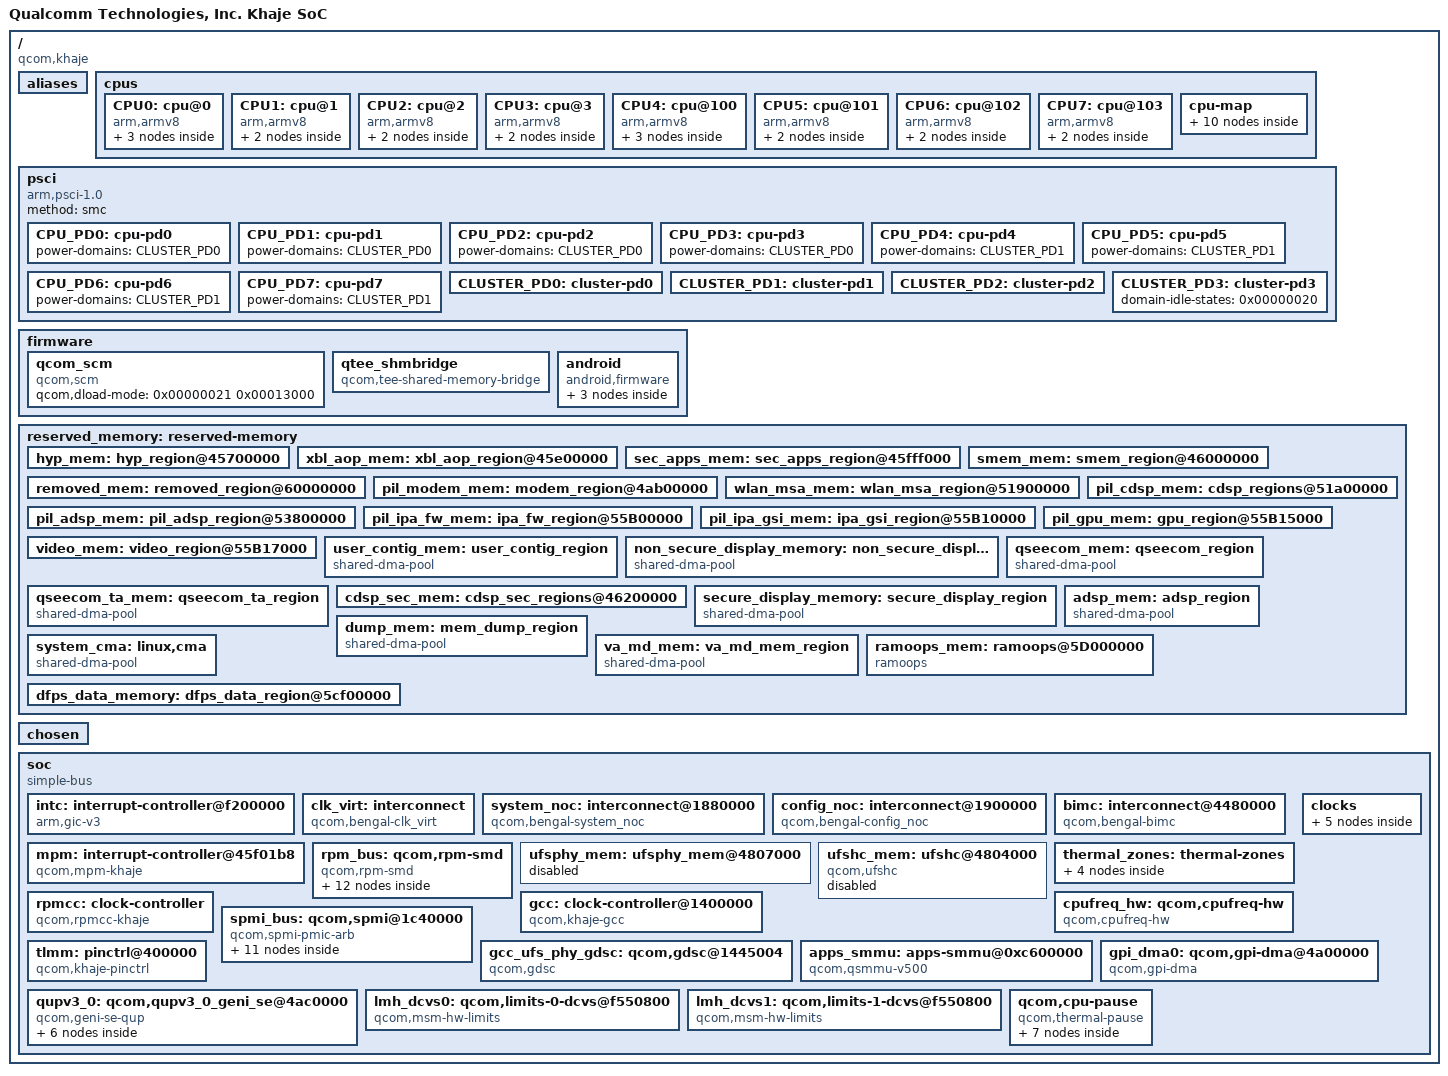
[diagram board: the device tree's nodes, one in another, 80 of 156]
/*
 * DT da SoC Khaje (subconjunto curado) gerada por tools/curate_dt.py.
 * Fonte: khaje-base-reference.dts, sha256 a0517193be3da264...
 * Nao revisado por upstream nem validado em hardware. Nao flashar.
 * Licenca: a definir antes de submissao (base Qualcomm, revisar).
 */

/ {
	model = "Qualcomm Technologies, Inc. Khaje SoC";
	compatible = "qcom,khaje";
	qcom,msm-id = <0x00000206 0x00010000>;
	interrupt-parent = <&intc>;
	#address-cells = <0x00000002>;
	#size-cells = <0x00000002>;
	qcom,board-id = <0x00000000 0x00000000>;
	aliases {
		ufshc1 = "/soc/ufshc@4804000";
		serial0 = "/soc/qcom,qupv3_0_geni_se@4ac0000/qcom,qup_uart@4a90000";
		hsuart0 = "/soc/qcom,qupv3_0_geni_se@4ac0000/qcom,qup_uart@4a8c000";
		spi0 = "/soc/qcom,qupv3_0_geni_se@4ac0000/spi@4a80000";
		i2c0 = "/soc/qcom,qupv3_0_geni_se@4ac0000/i2c@4a84000";
		i2c1 = "/soc/qcom,qupv3_0_geni_se@4ac0000/i2c@4a88000";
		i2c2 = "/soc/qcom,qupv3_0_geni_se@4ac0000/i2c@4a90000";
	};
	cpus {
		#address-cells = <0x00000002>;
		#size-cells = <0x00000000>;
		CPU0: cpu@0 {
			device_type = "cpu";
			compatible = "arm,armv8";
			reg = <0x00000000 0x00000000>;
			capacity-dmips-mhz = <0x00000400>;
			dynamic-power-coefficient = <0x00000064>;
			cpu-idle-states = <0x00000002>;
			power-domains = <&CPU_PD0>;
			power-domain-names = "psci";
			enable-method = "psci";
			next-level-cache = <&L2_0>;
			qcom,freq-domain = <&cpufreq_hw 0x00000000 0x00000007>;
			qcom,lmh-dcvs = <&lmh_dcvs0>;
			#cooling-cells = <0x00000002>;
			phandle = <0x00000011>;
			L2_0: l2-cache {
				compatible = "arm,arch-cache";
				cache-level = <0x00000002>;
				phandle = <0x00000004>;
			};
			L1_I_0: l1-icache {
				compatible = "arm,arch-cache";
				phandle = <0x00000127>;
			};
			L1_D_0: l1-dcache {
				compatible = "arm,arch-cache";
				phandle = <0x00000128>;
			};
		};
		CPU1: cpu@1 {
			device_type = "cpu";
			compatible = "arm,armv8";
			reg = <0x00000000 0x00000001>;
			capacity-dmips-mhz = <0x00000400>;
			dynamic-power-coefficient = <0x00000064>;
			cpu-idle-states = <0x00000002>;
			power-domains = <&CPU_PD1>;
			power-domain-names = "psci";
			enable-method = "psci";
			next-level-cache = <&L2_0>;
			qcom,freq-domain = <&cpufreq_hw 0x00000000 0x00000007>;
			qcom,lmh-dcvs = <&lmh_dcvs0>;
			phandle = <0x00000012>;
			L1_I_1: l1-icache {
				compatible = "arm,arch-cache";
				phandle = <0x00000129>;
			};
			L1_D_1: l1-dcache {
				compatible = "arm,arch-cache";
				phandle = <0x0000012a>;
			};
		};
		CPU2: cpu@2 {
			device_type = "cpu";
			compatible = "arm,armv8";
			reg = <0x00000000 0x00000002>;
			capacity-dmips-mhz = <0x00000400>;
			dynamic-power-coefficient = <0x00000064>;
			cpu-idle-states = <0x00000002>;
			power-domains = <&CPU_PD2>;
			power-domain-names = "psci";
			enable-method = "psci";
			next-level-cache = <&L2_0>;
			qcom,freq-domain = <&cpufreq_hw 0x00000000 0x00000007>;
			qcom,lmh-dcvs = <&lmh_dcvs0>;
			phandle = <0x00000013>;
			L1_I_2: l1-icache {
				compatible = "arm,arch-cache";
				phandle = <0x0000012b>;
			};
			L1_D_2: l1-dcache {
				compatible = "arm,arch-cache";
				phandle = <0x0000012c>;
			};
		};
		CPU3: cpu@3 {
			device_type = "cpu";
			compatible = "arm,armv8";
			reg = <0x00000000 0x00000003>;
			capacity-dmips-mhz = <0x00000400>;
			dynamic-power-coefficient = <0x00000064>;
			cpu-idle-states = <0x00000002>;
			power-domains = <&CPU_PD3>;
			power-domain-names = "psci";
			enable-method = "psci";
			next-level-cache = <&L2_0>;
			qcom,freq-domain = <&cpufreq_hw 0x00000000 0x00000007>;
			qcom,lmh-dcvs = <&lmh_dcvs0>;
			phandle = <0x00000014>;
			L1_I_3: l1-icache {
				compatible = "arm,arch-cache";
				phandle = <0x0000012d>;
			};
			L1_D_3: l1-dcache {
				compatible = "arm,arch-cache";
				phandle = <0x0000012e>;
			};
		};
		CPU4: cpu@100 {
			device_type = "cpu";
			compatible = "arm,armv8";
			reg = <0x00000000 0x00000100>;
			cpu-idle-states = <0x0000000a>;
			power-domains = <&CPU_PD4>;
			power-domain-names = "psci";
			enable-method = "psci";
			capacity-dmips-mhz = <0x00000666>;
			dynamic-power-coefficient = <0x0000011a>;
			next-level-cache = <&L2_1>;
			qcom,freq-domain = <&cpufreq_hw 0x00000001 0x00000007>;
			qcom,lmh-dcvs = <&lmh_dcvs1>;
			#cooling-cells = <0x00000002>;
			phandle = <0x00000015>;
			L2_1: l2-cache {
				compatible = "arm,arch-cache";
				cache-level = <0x00000002>;
				phandle = <0x0000000c>;
			};
			L1_I_100: l1-icache {
				compatible = "arm,arch-cache";
				phandle = <0x0000012f>;
			};
			L1_D_100: l1-dcache {
				compatible = "arm,arch-cache";
				phandle = <0x00000130>;
			};
		};
		CPU5: cpu@101 {
			device_type = "cpu";
			compatible = "arm,armv8";
			reg = <0x00000000 0x00000101>;
			capacity-dmips-mhz = <0x00000666>;
			dynamic-power-coefficient = <0x0000011a>;
			cpu-idle-states = <0x0000000a>;
			power-domains = <&CPU_PD5>;
			power-domain-names = "psci";
			enable-method = "psci";
			next-level-cache = <&L2_1>;
			qcom,freq-domain = <&cpufreq_hw 0x00000001 0x00000007>;
			qcom,lmh-dcvs = <&lmh_dcvs1>;
			phandle = <0x00000016>;
			L1_I_101: l1-icache {
				compatible = "arm,arch-cache";
				phandle = <0x00000131>;
			};
			L1_D_101: l1-dcache {
				compatible = "arm,arch-cache";
				phandle = <0x00000132>;
			};
		};
		CPU6: cpu@102 {
			device_type = "cpu";
			compatible = "arm,armv8";
			reg = <0x00000000 0x00000102>;
			capacity-dmips-mhz = <0x00000666>;
			dynamic-power-coefficient = <0x0000011a>;
			enable-method = "psci";
			cpu-idle-states = <0x0000000a>;
			power-domains = <&CPU_PD6>;
			power-domain-names = "psci";
			next-level-cache = <&L2_1>;
			qcom,freq-domain = <&cpufreq_hw 0x00000001 0x00000007>;
			qcom,lmh-dcvs = <&lmh_dcvs1>;
			phandle = <0x00000017>;
			L1_I_102: l1-icache {
				compatible = "arm,arch-cache";
				phandle = <0x00000133>;
			};
			L1_D_102: l1-dcache {
				compatible = "arm,arch-cache";
				phandle = <0x00000134>;
			};
		};
		CPU7: cpu@103 {
			device_type = "cpu";
			compatible = "arm,armv8";
			reg = <0x00000000 0x00000103>;
			capacity-dmips-mhz = <0x00000666>;
			dynamic-power-coefficient = <0x0000011a>;
			enable-method = "psci";
			cpu-idle-states = <0x0000000a>;
			power-domains = <&CPU_PD7>;
			power-domain-names = "psci";
			next-level-cache = <&L2_1>;
			qcom,freq-domain = <&cpufreq_hw 0x00000001 0x00000007>;
			qcom,lmh-dcvs = <&lmh_dcvs1>;
			phandle = <0x00000018>;
			L1_I_103: l1-icache {
				compatible = "arm,arch-cache";
				phandle = <0x00000135>;
			};
			L1_D_103: l1-dcache {
				compatible = "arm,arch-cache";
				phandle = <0x00000136>;
			};
		};
		cpu-map {
			cluster0 {
				core0 {
					cpu = <0x00000011>;
				};
				core1 {
					cpu = <0x00000012>;
				};
				core2 {
					cpu = <0x00000013>;
				};
				core3 {
					cpu = <0x00000014>;
				};
			};
			cluster1 {
				core0 {
					cpu = <0x00000015>;
				};
				core1 {
					cpu = <0x00000016>;
				};
				core2 {
					cpu = <0x00000017>;
				};
				core3 {
					cpu = <0x00000018>;
				};
			};
		};
	};
	psci {
		compatible = "arm,psci-1.0";
		method = "smc";
		CPU_PD0: cpu-pd0 {
			#power-domain-cells = <0x00000000>;
			power-domains = <&CLUSTER_PD0>;
			phandle = <0x00000003>;
		};
		CPU_PD1: cpu-pd1 {
			#power-domain-cells = <0x00000000>;
			power-domains = <&CLUSTER_PD0>;
			phandle = <0x00000007>;
		};
		CPU_PD2: cpu-pd2 {
			#power-domain-cells = <0x00000000>;
			power-domains = <&CLUSTER_PD0>;
			phandle = <0x00000008>;
		};
		CPU_PD3: cpu-pd3 {
			#power-domain-cells = <0x00000000>;
			power-domains = <&CLUSTER_PD0>;
			phandle = <0x00000009>;
		};
		CPU_PD4: cpu-pd4 {
			#power-domain-cells = <0x00000000>;
			power-domains = <&CLUSTER_PD1>;
			phandle = <0x0000000b>;
		};
		CPU_PD5: cpu-pd5 {
			#power-domain-cells = <0x00000000>;
			power-domains = <&CLUSTER_PD1>;
			phandle = <0x0000000e>;
		};
		CPU_PD6: cpu-pd6 {
			#power-domain-cells = <0x00000000>;
			power-domains = <&CLUSTER_PD1>;
			phandle = <0x0000000f>;
		};
		CPU_PD7: cpu-pd7 {
			#power-domain-cells = <0x00000000>;
			power-domains = <&CLUSTER_PD1>;
			phandle = <0x00000010>;
		};
		CLUSTER_PD0: cluster-pd0 {
			#power-domain-cells = <0x00000000>;
			power-domains = <&CLUSTER_PD2>;
			domain-idle-states = <0x0000001c>;
			phandle = <0x00000019>;
		};
		CLUSTER_PD1: cluster-pd1 {
			#power-domain-cells = <0x00000000>;
			power-domains = <&CLUSTER_PD2>;
			domain-idle-states = <0x0000001d>;
			phandle = <0x0000001a>;
		};
		CLUSTER_PD2: cluster-pd2 {
			#power-domain-cells = <0x00000000>;
			power-domains = <&CLUSTER_PD3>;
			domain-idle-states = <0x0000001f>;
			phandle = <0x0000001b>;
		};
		CLUSTER_PD3: cluster-pd3 {
			#power-domain-cells = <0x00000000>;
			domain-idle-states = <0x00000020>;
			phandle = <0x0000001e>;
		};
	};
	firmware: firmware {
		phandle = <0x00000137>;
		qcom_scm {
			compatible = "qcom,scm";
			qcom,dload-mode = <0x00000021 0x00013000>;
		};
		qtee_shmbridge {
			compatible = "qcom,tee-shared-memory-bridge";
		};
		android {
			compatible = "android,firmware";
			vbmeta {
				compatible = "android,vbmeta";
				parts = "vbmeta,boot,system,vendor,dtbo,recovery";
			};
			fstab {
				compatible = "android,fstab";
				vendor {
					compatible = "android,vendor";
					dev = "/dev/block/platform/soc/4744000.sdhci/by-name/vendor";
					type = "ext4";
					mnt_flags = "ro,barrier=1,discard";
					fsmgr_flags = "wait,slotselect,avb";
					status = "okay";
				};
			};
		};
	};
	reserved_memory: reserved-memory {
		#address-cells = <0x00000002>;
		#size-cells = <0x00000002>;
		ranges;
		phandle = <0x00000138>;
		hyp_mem: hyp_region@45700000 {
			no-map;
			reg = <0x00000000 0x45700000 0x00000000 0x00600000>;
			phandle = <0x00000139>;
		};
		xbl_aop_mem: xbl_aop_region@45e00000 {
			no-map;
			reg = <0x00000000 0x45e00000 0x00000000 0x00140000>;
			phandle = <0x0000013a>;
		};
		sec_apps_mem: sec_apps_region@45fff000 {
			no-map;
			reg = <0x00000000 0x45fff000 0x00000000 0x00001000>;
			phandle = <0x0000013b>;
		};
		smem_mem: smem_region@46000000 {
			no-map;
			reg = <0x00000000 0x46000000 0x00000000 0x00200000>;
			phandle = <0x000000ca>;
		};
		removed_mem: removed_region@60000000 {
			no-map;
			reg = <0x00000000 0x60000000 0x00000000 0x03900000>;
			phandle = <0x0000013c>;
		};
		pil_modem_mem: modem_region@4ab00000 {
			no-map;
			reg = <0x00000000 0x4ab00000 0x00000000 0x06900000>;
			phandle = <0x000000da>;
		};
		wlan_msa_mem: wlan_msa_region@51900000 {
			no-map;
			reg = <0x00000000 0x51900000 0x00000000 0x00100000>;
			phandle = <0x0000013d>;
		};
		pil_cdsp_mem: cdsp_regions@51a00000 {
			no-map;
			reg = <0x00000000 0x51a00000 0x00000000 0x01a00000>;
			phandle = <0x00000096>;
		};
		pil_adsp_mem: pil_adsp_region@53800000 {
			no-map;
			reg = <0x00000000 0x53800000 0x00000000 0x02300000>;
			phandle = <0x00000091>;
		};
		pil_ipa_fw_mem: ipa_fw_region@55B00000 {
			no-map;
			reg = <0x00000000 0x55b00000 0x00000000 0x00010000>;
			phandle = <0x000000e0>;
		};
		pil_ipa_gsi_mem: ipa_gsi_region@55B10000 {
			no-map;
			reg = <0x00000000 0x55b10000 0x00000000 0x00005000>;
			phandle = <0x0000013e>;
		};
		pil_gpu_mem: gpu_region@55B15000 {
			no-map;
			reg = <0x00000000 0x55b15000 0x00000000 0x00002000>;
			phandle = <0x0000013f>;
		};
		video_mem: video_region@55B17000 {
			no-map;
			reg = <0x00000000 0x55b17000 0x00000000 0x00700000>;
			phandle = <0x00000140>;
		};
		user_contig_mem: user_contig_region {
			compatible = "shared-dma-pool";
			alloc-ranges = <0x00000000 0x00000000 0x00000000 0xffffffff>;
			reusable;
			alignment = <0x00000000 0x00400000>;
			size = <0x00000000 0x01000000>;
			phandle = <0x00000089>;
		};
		non_secure_display_memory: non_secure_display_region {
			compatible = "shared-dma-pool";
			reusable;
			alloc-ranges = <0x00000000 0x00000000 0x00000000 0xffffffff>;
			size = <0x00000000 0x0a400000>;
			alignment = <0x00000000 0x00400000>;
			phandle = <0x000000f8>;
		};
		qseecom_mem: qseecom_region {
			compatible = "shared-dma-pool";
			alloc-ranges = <0x00000000 0x00000000 0x00000000 0xffffffff>;
			reusable;
			alignment = <0x00000000 0x00400000>;
			size = <0x00000000 0x01400000>;
			phandle = <0x00000087>;
		};
		qseecom_ta_mem: qseecom_ta_region {
			compatible = "shared-dma-pool";
			alloc-ranges = <0x00000000 0x00000000 0x00000000 0xffffffff>;
			reusable;
			alignment = <0x00000000 0x00400000>;
			size = <0x00000000 0x01000000>;
			phandle = <0x00000088>;
		};
		cdsp_sec_mem: cdsp_sec_regions@46200000 {
			no-map;
			reg = <0x00000000 0x46200000 0x00000000 0x01e00000>;
			phandle = <0x000000f6>;
		};
		secure_display_memory: secure_display_region {
			compatible = "shared-dma-pool";
			alloc-ranges = <0x00000000 0x00000000 0x00000000 0xffffffff>;
			reusable;
			alignment = <0x00000000 0x00400000>;
			size = <0x00000000 0x05c00000>;
			phandle = <0x000000f7>;
		};
		adsp_mem: adsp_region {
			compatible = "shared-dma-pool";
			alloc-ranges = <0x00000000 0x00000000 0x00000000 0xffffffff>;
			reusable;
			alignment = <0x00000000 0x00400000>;
			size = <0x00000000 0x00800000>;
			phandle = <0x000000d1>;
		};
		dump_mem: mem_dump_region {
			compatible = "shared-dma-pool";
			alloc-ranges = <0x00000000 0x00000000 0x00000000 0xffffffff>;
			reusable;
			size = <0x00000000 0x00800000>;
			phandle = <0x00000099>;
		};
		system_cma: linux,cma {
			compatible = "shared-dma-pool";
			alloc-ranges = <0x00000000 0x00000000 0x00000000 0xffffffff>;
			reusable;
			alignment = <0x00000000 0x00400000>;
			size = <0x00000000 0x02000000>;
			linux,cma-default;
			phandle = <0x000000ff>;
		};
		va_md_mem: va_md_mem_region {
			compatible = "shared-dma-pool";
			alloc-ranges = <0x00000000 0x00000000 0x00000000 0xffffffff>;
			reusable;
			size = <0x00000000 0x01000000>;
			phandle = <0x000000c8>;
		};
		ramoops_mem: ramoops@5D000000 {
			compatible = "ramoops";
			reg = <0x00000000 0x5d000000 0x00000000 0x00200000>;
			record-size = <0x00040000>;
			pmsg-size = <0x00100000>;
			console-size = <0x00080000>;
			phandle = <0x00000141>;
		};
		dfps_data_memory: dfps_data_region@5cf00000 {
			phandle = <0x000002ef>;
			label = "dfps_data_region";
			reg = <0x00000000 0x5cf00000 0x00000000 0x00100000>;
		};
	};
	chosen {
	};
	soc: soc {
		#address-cells = <0x00000001>;
		#size-cells = <0x00000001>;
		ranges = <0x00000000 0x00000000 0x00000000 0xffffffff>;
		compatible = "simple-bus";
		phandle = <0x00000142>;
		intc: interrupt-controller@f200000 {
			compatible = "arm,gic-v3";
			#interrupt-cells = <0x00000003>;
			interrupt-controller;
			interrupt-parent = <&intc>;
			#redistributor-regions = <0x00000001>;
			redistributor-stride = <0x00000000 0x00020000>;
			reg = <0x0f200000 0x00010000 0x0f300000 0x00100000>;
			interrupts = <0x00000001 0x00000009 0x00000004>;
			phandle = <0x00000001>;
		};
		clk_virt: interconnect {
			compatible = "qcom,bengal-clk_virt";
			qcom,keepalive;
			#interconnect-cells = <0x00000001>;
			clock-names = "bus", "bus_a";
			clocks = <&rpmcc 0x0000006a &rpmcc 0x0000006b>;
			phandle = <0x00000101>;
		};
		system_noc: interconnect@1880000 {
			compatible = "qcom,bengal-system_noc";
			reg = <0x01880000 0x0005f080>;
			#interconnect-cells = <0x00000001>;
			qcom,keepalive;
			clock-names = "bus", "bus_a";
			clocks = <&rpmcc 0x00000004 &rpmcc 0x00000005 &gcc 0x00000038 &gcc 0x00000074>;
			phandle = <0x0000008a>;
		};
		config_noc: interconnect@1900000 {
			compatible = "qcom,bengal-config_noc";
			reg = <0x01900000 0x00006200>;
			#interconnect-cells = <0x00000001>;
			qcom,keepalive;
			clock-names = "bus", "bus_a";
			clocks = <&rpmcc 0x0000001c &rpmcc 0x0000001d>;
			phandle = <0x0000008c>;
		};
		bimc: interconnect@4480000 {
			compatible = "qcom,bengal-bimc";
			reg = <0x04480000 0x00080000>;
			#interconnect-cells = <0x00000001>;
			qcom,util-factor = <0x00000099>;
			qcom,keepalive;
			clock-names = "bus", "bus_a";
			clocks = <&rpmcc 0x00000006 &rpmcc 0x00000007>;
			phandle = <0x0000008b>;
		};
		mpm: interrupt-controller@45f01b8 {
			compatible = "qcom,mpm-khaje", "qcom,mpm";
			reg = <0x045f01b8 0x00001000 0x0f111008 0x00000004 0x0f121000 0x00001000>;
			reg-names = "vmpm", "ipc", "timer";
			interrupts = <0x00000000 0x000000c5 0x00000001>;
			qcom,num-mpm-irqs = <0x00000060>;
			interrupt-controller;
			interrupt-parent = <&intc>;
			#interrupt-cells = <0x00000002>;
			phandle = <0x000000d5>;
		};
		rpm_bus: qcom,rpm-smd {
			compatible = "qcom,rpm-smd";
			rpm-channel-name = "rpm_requests";
			interrupts = <0x00000000 0x000000c2 0x00000001>;
			power-domains = <&CLUSTER_PD3>;
			rpm-channel-type = <0x0000000f>;
			phandle = <0x000001a5>;
			rpm-regulator-smpa3 {
				compatible = "qcom,rpm-smd-regulator-resource";
				qcom,resource-name = "rwcx";
				qcom,resource-id = <0x00000000>;
				qcom,regulator-type = <0x00000001>;
				qcom,hpm-min-load = <0x000186a0>;
				status = "okay";
				VDD_CX_LEVEL: VDD_GFX_LEVEL: VDD_MSS_LEVEL: S3A_LEVEL: pm6125_s3_level: regulator-s3-level {
					compatible = "qcom,rpm-smd-regulator";
					regulator-name = "pm6125_s3_level";
					qcom,set = <0x00000003>;
					regulator-min-microvolt = <0x00000010>;
					regulator-max-microvolt = <0x00000200>;
					qcom,use-voltage-level;
					phandle = <0x00000095>;
				};
			};
			rpm-regulator-smpa5 {
				compatible = "qcom,rpm-smd-regulator-resource";
				qcom,resource-name = "rwmx";
				qcom,resource-id = <0x00000000>;
				qcom,regulator-type = <0x00000001>;
				qcom,hpm-min-load = <0x000186a0>;
				status = "okay";
				VDD_MX_LEVEL: S5A_LEVEL: pm6125_s5_level: regulator-s5-level {
					compatible = "qcom,rpm-smd-regulator";
					regulator-name = "pm6125_s5_level";
					qcom,set = <0x00000003>;
					regulator-min-microvolt = <0x00000010>;
					regulator-max-microvolt = <0x00000200>;
					qcom,use-voltage-level;
					phandle = <0x0000008e>;
				};
			};
			rpm-regulator-ldoa4 {
				compatible = "qcom,rpm-smd-regulator-resource";
				qcom,resource-name = "ldoa";
				qcom,resource-id = <0x00000004>;
				qcom,regulator-type = <0x00000000>;
				qcom,regulator-hw-type = "pmic5-ldo";
				qcom,hpm-min-load = <0x00002710>;
				status = "okay";
				pm6125_l4: L4A: regulator-l4 {
					compatible = "qcom,rpm-smd-regulator";
					regulator-name = "pm6125_l4";
					qcom,set = <0x00000003>;
					status = "okay";
					regulator-min-microvolt = <0x000afc80>;
					regulator-max-microvolt = <0x00100590>;
					qcom,init-voltage = <0x000d6d80>;
					phandle = <0x000000f2>;
				};
			};
			rpm-regulator-ldoa11 {
				compatible = "qcom,rpm-smd-regulator-resource";
				qcom,resource-name = "ldoa";
				qcom,resource-id = <0x0000000b>;
				qcom,regulator-type = <0x00000000>;
				qcom,regulator-hw-type = "pmic5-ldo";
				qcom,hpm-min-load = <0x00002710>;
				status = "okay";
				pm6125_l11: L11A: regulator-l11 {
					compatible = "qcom,rpm-smd-regulator";
					regulator-name = "pm6125_l11";
					qcom,set = <0x00000003>;
					status = "okay";
					regulator-min-microvolt = <0x0019f0a0>;
					regulator-max-microvolt = <0x001dc130>;
					qcom,init-voltage = <0x001b7740>;
					phandle = <0x000001b2>;
				};
			};
			rpm-regulator-ldoa18 {
				compatible = "qcom,rpm-smd-regulator-resource";
				qcom,resource-name = "ldoa";
				qcom,resource-id = <0x00000012>;
				qcom,regulator-type = <0x00000000>;
				qcom,regulator-hw-type = "pmic5-ldo";
				qcom,hpm-min-load = <0x00002710>;
				status = "okay";
				pm6125_l18: L18A: regulator-l18 {
					compatible = "qcom,rpm-smd-regulator";
					regulator-name = "pm6125_l18";
					qcom,set = <0x00000003>;
					status = "okay";
					regulator-min-microvolt = <0x0010c8e0>;
					regulator-max-microvolt = <0x0013d620>;
					qcom,init-voltage = <0x0012cc80>;
					phandle = <0x000000f5>;
				};
			};
			rpm-regulator-ldoa24 {
				compatible = "qcom,rpm-smd-regulator-resource";
				qcom,resource-name = "ldoa";
				qcom,resource-id = <0x00000018>;
				qcom,regulator-type = <0x00000000>;
				qcom,regulator-hw-type = "pmic5-ldo";
				qcom,hpm-min-load = <0x00002710>;
				status = "okay";
				pm6125_l24: L24A: regulator-l24 {
					compatible = "qcom,rpm-smd-regulator";
					regulator-name = "pm6125_l24";
					qcom,set = <0x00000003>;
					status = "okay";
					regulator-min-microvolt = <0x002932e0>;
					regulator-max-microvolt = <0x003613c0>;
					qcom,init-voltage = <0x002d2a80>;
					phandle = <0x000001b9>;
				};
			};
		};
		ufsphy_mem: ufsphy_mem@4807000 {
			reg = <0x04807000 0x00000e00>;
			reg-names = "phy_mem";
			#phy-cells = <0x00000000>;
			lanes-per-direction = <0x00000002>;
			clock-names = "ref_clk_src", "ref_aux_clk", "qref_clk", "rx_sym0_mux_clk", "rx_sym1_mux_clk", "tx_sym0_mux_clk", "rx_sym0_phy_clk", "rx_sym1_phy_clk", "tx_sym0_phy_clk";
			clocks = <&rpmcc 0x00000000 &gcc 0x0000007b &gcc 0x00000075 &gcc 0x0000007e &gcc 0x00000080 &gcc 0x00000082 &gcc 0x0000007d &gcc 0x0000007f &gcc 0x00000081>;
			resets = <&ufshc_mem 0x00000000>;
			status = "disabled";
			phandle = <0x0000009e>;
		};
		ufshc_mem: ufshc@4804000 {
			compatible = "qcom,ufshc";
			reg = <0x04804000 0x00003000 0x04810000 0x00008000>;
			reg-names = "ufs_mem", "ufs_ice";
			interrupts = <0x00000000 0x00000164 0x00000004>;
			phys = <&ufsphy_mem>;
			phy-names = "ufsphy";
			qcom,prime-mask = <0x00000080>;
			qcom,silver-mask = <0x0000000f>;
			limit-rx-hs-gear = <0x00000003>;
			limit-tx-hs-gear = <0x00000003>;
			lanes-per-direction = <0x00000002>;
			limit-phy-submode = <0x00000000>;
			dev-ref-clk-freq = <0x00000000>;
			#reset-cells = <0x00000001>;
			nvmem-cells = <0x0000009a>;
			nvmem-cell-names = "boot_conf";
			spm-level = <0x00000003>;
			rpm-level = <0x00000003>;
			clock-names = "core_clk", "bus_aggr_clk", "iface_clk", "core_clk_unipro", "core_clk_ice", "ref_clk", "tx_lane0_sync_clk", "rx_lane0_sync_clk", "rx_lane1_sync_clk";
			clocks = <&gcc 0x00000077 &gcc 0x00000073 &gcc 0x00000076 &gcc 0x00000083 &gcc 0x00000079 &rpmcc 0x00000000 &gcc 0x00000081 &gcc 0x0000007d &gcc 0x0000007f>;
			freq-table-hz = <0x02faf080 0x0bebc200 0x00000000 0x00000000 0x00000000 0x00000000 0x023c3460 0x08f0d180 0x047868c0 0x11e1a300 0x00000000 0x00000000 0x00000000 0x00000000 0x00000000 0x00000000 0x00000000 0x00000000>;
			interconnects = <&system_noc 0x0000001d &bimc 0x00000200 &bimc 0x00000000 &config_noc 0x0000023e>;
			interconnect-names = "ufs-ddr", "cpu-ufs";
			qcom,ufs-bus-bw,name = "ufshc_mem";
			qcom,ufs-bus-bw,num-cases = <0x00000016>;
			qcom,ufs-bus-bw,num-paths = <0x00000002>;
			qcom,ufs-bus-bw,vectors-KBps = <0x0000007b 0x00000200 0x00000000 0x00000000 0x00000001 0x000002f5 0x00000000 0x00000000 0x0000007b 0x00000200 0x0000039a 0x00000000 0x00000001 0x000002f5 0x000003e8 0x00000000 0x0000007b 0x00000200 0x00000734 0x00000000 0x00000001 0x000002f5 0x000003e8 0x00000000 0x0000007b 0x00000200 0x00000e68 0x00000000 0x00000001 0x000002f5 0x000003e8 0x00000000 0x0000007b 0x00000200 0x00001cd0 0x00000000 0x00000001 0x000002f5 0x000003e8 0x00000000 0x0000007b 0x00000200 0x00000734 0x00000000 0x00000001 0x000002f5 0x000003e8 0x00000000 0x0000007b 0x00000200 0x00000e68 0x00000000 0x00000001 0x000002f5 0x000003e8 0x00000000 0x0000007b 0x00000200 0x00001cd0 0x00000000 0x00000001 0x000002f5 0x000003e8 0x00000000 0x0000007b 0x00000200 0x000039a0 0x00000000 0x00000001 0x000002f5 0x000003e8 0x00000000 0x0000007b 0x00000200 0x0001f334 0x00000000 0x00000001 0x000002f5 0x000003e8 0x00000000 0x0000007b 0x00000200 0x0003e667 0x00000000 0x00000001 0x000002f5 0x000003e8 0x00000000 0x0000007b 0x00000200 0x00200000 0x00000000 0x00000001 0x000002f5 0x00019000 0x00000000 0x0000007b 0x00000200 0x0003e667 0x00000000 0x00000001 0x000002f5 0x000003e8 0x00000000 0x0000007b 0x00000200 0x0007cccd 0x00000000 0x00000001 0x000002f5 0x000003e8 0x00000000 0x0000007b 0x00000200 0x00400000 0x00000000 0x00000001 0x000002f5 0x00032000 0x00000000 0x0000007b 0x00000200 0x000247ae 0x00000000 0x00000001 0x000002f5 0x000003e8 0x00000000 0x0000007b 0x00000200 0x00048ccd 0x00000000 0x00000001 0x000002f5 0x000003e8 0x00000000 0x0000007b 0x00000200 0x00200000 0x00000000 0x00000001 0x000002f5 0x00019000 0x00000000 0x0000007b 0x00000200 0x00048ccd 0x00000000 0x00000001 0x000002f5 0x000003e8 0x00000000 0x0000007b 0x00000200 0x0009199a 0x00000000 0x00000001 0x000002f5 0x000003e8 0x00000000 0x0000007b 0x00000200 0x00400000 0x00000000 0x00000001 0x000002f5 0x00032000 0x00064000 0x0000007b 0x00000200 0x0074a000 0x00000000 0x00000001 0x000002f5 0x0004b000 0x00000000>;
			qcom,bus-vector-names = "MIN", "PWM_G1_L1", "PWM_G2_L1", "PWM_G3_L1", "PWM_G4_L1", "PWM_G1_L2", "PWM_G2_L2", "PWM_G3_L2", "PWM_G4_L2", "HS_RA_G1_L1", "HS_RA_G2_L1", "HS_RA_G3_L1", "HS_RA_G1_L2", "HS_RA_G2_L2", "HS_RA_G3_L2", "HS_RB_G1_L1", "HS_RB_G2_L1", "HS_RB_G3_L1", "HS_RB_G1_L2", "HS_RB_G2_L2", "HS_RB_G3_L2", "MAX";
			reset-names = "core_reset";
			non-removable;
			status = "disabled";
			iommus = <&apps_smmu 0x00000100 0x00000000>;
			qcom,iommu-dma = "fastmap";
			phandle = <0x0000009d>;
		};
		thermal_zones: thermal-zones {
			phandle = <0x000001c0>;
			pm6125-tz {
				polling-delay-passive = <0x00000064>;
				polling-delay = <0x00000000>;
				thermal-governor = "step_wise";
				thermal-sensors = <&pm6125_tz>;
				wake-capable-sensor;
				trips {
					pm6125_trip0: trip0 {
						temperature = <0x00017318>;
						hysteresis = <0x00000000>;
						type = "passive";
						phandle = <0x000001c1>;
					};
					pm6125_trip1: trip1 {
						temperature = <0x0001c138>;
						hysteresis = <0x00000000>;
						type = "passive";
						phandle = <0x000001c2>;
					};
				};
			};
		};
		clocks {
			sleep_clk: sleep_clk {
				compatible = "fixed-clock";
				clock-frequency = <0x00007ffc>;
				clock-output-names = "sleep_clk";
				#clock-cells = <0x00000000>;
				phandle = <0x000000be>;
			};
			ufs_phy_rx_symbol_0_clk: ufs_phy_rx_symbol_0_clk {
				compatible = "fixed-clock";
				clock-frequency = <0x000003e8>;
				clock-output-names = "ufs_phy_rx_symbol_0_clk";
				#clock-cells = <0x00000000>;
				phandle = <0x000000bf>;
			};
			ufs_phy_rx_symbol_1_clk: ufs_phy_rx_symbol_1_clk {
				compatible = "fixed-clock";
				clock-frequency = <0x000003e8>;
				clock-output-names = "ufs_phy_rx_symbol_1_clk";
				#clock-cells = <0x00000000>;
				phandle = <0x000000c0>;
			};
			ufs_phy_tx_symbol_0_clk: ufs_phy_tx_symbol_0_clk {
				compatible = "fixed-clock";
				clock-frequency = <0x000003e8>;
				clock-output-names = "ufs_phy_tx_symbol_0_clk";
				#clock-cells = <0x00000000>;
				phandle = <0x000000c1>;
			};
			usb3_phy_wrapper_gcc_usb30_pipe_clk: usb3_phy_wrapper_gcc_usb30_pipe_clk {
				compatible = "fixed-clock";
				clock-frequency = <0x000003e8>;
				clock-output-names = "usb3_phy_wrapper_gcc_usb30_pipe_clk";
				#clock-cells = <0x00000000>;
				phandle = <0x000000c2>;
			};
		};
		rpmcc: clock-controller {
			compatible = "qcom,rpmcc-khaje";
			#clock-cells = <0x00000001>;
			phandle = <0x00000023>;
		};
		gcc: clock-controller@1400000 {
			compatible = "qcom,khaje-gcc", "syscon";
			reg = <0x01400000 0x001f0000>;
			reg-names = "cc_base";
			vdd_cx-supply = <&VDD_CX_LEVEL>;
			vdd_mx-supply = <&VDD_MX_LEVEL>;
			clocks = <&rpmcc 0x00000000 &rpmcc 0x00000001 &sleep_clk &ufs_phy_rx_symbol_0_clk &ufs_phy_rx_symbol_1_clk &ufs_phy_tx_symbol_0_clk &usb3_phy_wrapper_gcc_usb30_pipe_clk>;
			clock-names = "bi_tcxo", "bi_tcxo_ao", "sleep_clk", "ufs_phy_rx_symbol_0_clk", "ufs_phy_rx_symbol_1_clk", "ufs_phy_tx_symbol_0_clk", "usb3_phy_wrapper_gcc_usb30_pipe_clk";
			#clock-cells = <0x00000001>;
			#reset-cells = <0x00000001>;
			qcom,critical-devices = <0x000000c3>;
			phandle = <0x00000081>;
		};
		cpufreq_hw: qcom,cpufreq-hw {
			compatible = "qcom,cpufreq-hw";
			reg = <0x0f521000 0x00001000 0x0f523000 0x00001000>;
			reg-names = "freq-domain0", "freq-domain1";
			clocks = <&rpmcc 0x00000000 &gcc 0x000000a2>;
			clock-names = "xo", "alternate";
			qcom,no-accumulative-counter;
			qcom,max-lut-entries = <0x0000000c>;
			#freq-domain-cells = <0x00000002>;
			phandle = <0x00000005>;
		};
		spmi_bus: qcom,spmi@1c40000 {
			compatible = "qcom,spmi-pmic-arb";
			reg = <0x01c40000 0x00001100 0x01e00000 0x02000000 0x03e00000 0x00100000 0x03f00000 0x000a0000 0x01c0a000 0x00026000>;
			reg-names = "core", "chnls", "obsrvr", "intr", "cnfg";
			interrupt-names = "periph_irq";
			interrupts-extended = <&mpm 0x00000056 0x00000004>;
			qcom,ee = <0x00000000>;
			qcom,channel = <0x00000000>;
			#address-cells = <0x00000001>;
			#size-cells = <0x00000001>;
			interrupt-controller;
			#interrupt-cells = <0x00000004>;
			cell-index = <0x00000000>;
			phandle = <0x000001cc>;
			qcom,pm6125@0 {
				compatible = "qcom,spmi-pmic";
				reg = <0x00000000 0x00000000>;
				#address-cells = <0x00000001>;
				#size-cells = <0x00000000>;
				pm6125_vadc: vadc@3100 {
					compatible = "qcom,spmi-adc5";
					reg = <0x00003100>;
					#address-cells = <0x00000001>;
					#size-cells = <0x00000000>;
					interrupts = <0x00000000 0x00000031 0x00000000 0x00000001>;
					interrupt-names = "eoc-int-en-set";
					qcom,adc-vdd-reference = <0x00000753>;
					#io-channel-cells = <0x00000001>;
					io-channel-ranges;
					pinctrl-names = "default";
					pinctrl-0 = <0x000000d6 0x000000d7>;
					phandle = <0x000000d8>;
				};
				pm6125_adc_tm: adc_tm@3500 {
					compatible = "qcom,spmi-adc-tm5";
					reg = <0x00003500>;
					interrupts = <0x00000000 0x00000035 0x00000000 0x00000001>;
					interrupt-names = "pm-adc-tm5";
					#address-cells = <0x00000001>;
					#size-cells = <0x00000000>;
					#thermal-sensor-cells = <0x00000001>;
					phandle = <0x000000bc>;
				};
				pm6125_tz: qcom,temp-alarm@2400 {
					compatible = "qcom,spmi-temp-alarm";
					reg = <0x00002400>;
					interrupts = <0x00000000 0x00000024 0x00000000 0x00000003>;
					#thermal-sensor-cells = <0x00000000>;
					qcom,temperature-threshold-set = <0x00000001>;
					phandle = <0x0000009f>;
				};
				pm6125_gpios: pinctrl@c000 {
					compatible = "qcom,pm6125-gpio";
					reg = <0x0000c000>;
					gpio-controller;
					#gpio-cells = <0x00000002>;
					interrupt-controller;
					#interrupt-cells = <0x00000002>;
					phandle = <0x000001cd>;
					camera_therm {
						camera_therm_default: camera_therm_default {
							pins = "gpio3";
							bias-high-impedance;
							phandle = <0x000000d6>;
						};
					};
					emmc_therm {
						emmc_therm_default: emmc_therm_default {
							pins = "gpio4";
							bias-high-impedance;
							phandle = <0x000000d7>;
						};
					};
				};
			};
			qcom,pm6125@1 {
				compatible = "qcom,spmi-pmic";
				reg = <0x00000001 0x00000000>;
				#address-cells = <0x00000001>;
				#size-cells = <0x00000000>;
				pm6125_pwm: qcom,pwms@b300 {
					status = "disabled";
					compatible = "qcom,pwm-lpg";
					reg = <0x0000b300>;
					reg-names = "lpg-base";
					qcom,num-lpg-channels = <0x00000001>;
					#pwm-cells = <0x00000002>;
					phandle = <0x000001cf>;
				};
			};
		};
		gcc_ufs_phy_gdsc: qcom,gdsc@1445004 {
			compatible = "qcom,gdsc";
			reg = <0x01445004 0x00000004>;
			regulator-name = "gcc_ufs_phy_gdsc";
			status = "okay";
			phandle = <0x000001df>;
		};
		apps_smmu: apps-smmu@0xc600000 {
			status = "okay";
			compatible = "qcom,qsmmu-v500";
			reg = <0x0c600000 0x00080000 0x0c782000 0x00000020>;
			reg-names = "base", "tcu-base";
			#iommu-cells = <0x00000002>;
			qcom,skip-init;
			qcom,use-3-lvl-tables;
			qcom,handoff-smrs = <0x00000420 0x00000002>;
			#global-interrupts = <0x00000001>;
			#size-cells = <0x00000001>;
			#address-cells = <0x00000001>;
			ranges;
			interrupts = <0x00000000 0x00000051 0x00000004 0x00000000 0x00000058 0x00000004 0x00000000 0x00000059 0x00000004 0x00000000 0x0000005a 0x00000004 0x00000000 0x0000005b 0x00000004 0x00000000 0x0000005c 0x00000004 0x00000000 0x0000005d 0x00000004 0x00000000 0x0000005e 0x00000004 0x00000000 0x0000005f 0x00000004 0x00000000 0x00000060 0x00000004 0x00000000 0x00000061 0x00000004 0x00000000 0x00000062 0x00000004 0x00000000 0x00000063 0x00000004 0x00000000 0x00000064 0x00000004 0x00000000 0x00000065 0x00000004 0x00000000 0x00000066 0x00000004 0x00000000 0x00000067 0x00000004 0x00000000 0x00000068 0x00000004 0x00000000 0x00000069 0x00000004 0x00000000 0x0000006a 0x00000004 0x00000000 0x0000006b 0x00000004 0x00000000 0x0000006c 0x00000004 0x00000000 0x0000006d 0x00000004 0x00000000 0x0000006e 0x00000004 0x00000000 0x0000006f 0x00000004 0x00000000 0x00000070 0x00000004 0x00000000 0x00000071 0x00000004 0x00000000 0x00000072 0x00000004 0x00000000 0x00000073 0x00000004 0x00000000 0x00000074 0x00000004 0x00000000 0x00000075 0x00000004 0x00000000 0x00000076 0x00000004 0x00000000 0x00000077 0x00000004 0x00000000 0x00000078 0x00000004 0x00000000 0x00000079 0x00000004 0x00000000 0x0000007a 0x00000004 0x00000000 0x0000007b 0x00000004 0x00000000 0x0000007c 0x00000004 0x00000000 0x0000007d 0x00000004 0x00000000 0x0000007e 0x00000004 0x00000000 0x0000007f 0x00000004 0x00000000 0x00000080 0x00000004 0x00000000 0x00000081 0x00000004 0x00000000 0x00000082 0x00000004 0x00000000 0x00000083 0x00000004 0x00000000 0x00000084 0x00000004 0x00000000 0x00000085 0x00000004 0x00000000 0x00000086 0x00000004 0x00000000 0x00000087 0x00000004 0x00000000 0x00000088 0x00000004 0x00000000 0x00000089 0x00000004 0x00000000 0x0000008a 0x00000004 0x00000000 0x0000008b 0x00000004 0x00000000 0x0000008c 0x00000004 0x00000000 0x0000008d 0x00000004 0x00000000 0x0000008e 0x00000004 0x00000000 0x0000008f 0x00000004 0x00000000 0x00000090 0x00000004 0x00000000 0x00000091 0x00000004 0x00000000 0x00000092 0x00000004 0x00000000 0x00000093 0x00000004 0x00000000 0x00000094 0x00000004 0x00000000 0x00000095 0x00000004 0x00000000 0x00000096 0x00000004 0x00000000 0x00000097 0x00000004>;
			interconnects = <&bimc 0x00000000 &system_noc 0x0000023c>;
			qcom,active-only;
			qcom,actlr = <0x00000400 0x000003ff 0x00000103 0x00000800 0x000003ff 0x00000103>;
			phandle = <0x0000007e>;
		};
		tlmm: pinctrl@400000 {
			compatible = "qcom,khaje-pinctrl";
			reg = <0x00400000 0x00c00000>;
			interrupts = <0x00000000 0x000000e3 0x00000004>;
			gpio-controller;
			#gpio-cells = <0x00000002>;
			interrupt-controller;
			#interrupt-cells = <0x00000002>;
			wakeup-parent = <0x000000d5>;
			phandle = <0x00000082>;
		};
		gpi_dma0: qcom,gpi-dma@4a00000 {
			compatible = "qcom,gpi-dma";
			#dma-cells = <0x00000005>;
			reg = <0x04a00000 0x00060000>;
			reg-names = "gpi-top";
			interrupts = <0x00000000 0x0000014f 0x00000004 0x00000000 0x00000150 0x00000004 0x00000000 0x00000151 0x00000004 0x00000000 0x00000152 0x00000004 0x00000000 0x00000153 0x00000004 0x00000000 0x00000154 0x00000004 0x00000000 0x00000155 0x00000004 0x00000000 0x00000156 0x00000004 0x00000000 0x00000157 0x00000004 0x00000000 0x00000158 0x00000004>;
			qcom,max-num-gpii = <0x0000000a>;
			qcom,gpii-mask = <0x0000000f>;
			qcom,ev-factor = <0x00000002>;
			iommus = <&apps_smmu 0x000000f6 0x00000000>;
			qcom,gpi-ee-offset = <0x00010000>;
			qcom,iommu-dma-addr-pool = <0x00100000 0x00100000>;
			status = "okay";
			phandle = <0x00000105>;
		};
		qupv3_0: qcom,qupv3_0_geni_se@4ac0000 {
			compatible = "qcom,geni-se-qup";
			reg = <0x04ac0000 0x00002000>;
			#address-cells = <0x00000001>;
			#size-cells = <0x00000001>;
			clock-names = "m-ahb", "s-ahb";
			clocks = <&gcc 0x00000068 &gcc 0x00000069>;
			iommus = <&apps_smmu 0x000000e3 0x00000000>;
			qcom,iommu-dma-addr-pool = <0x40000000 0x10000000>;
			qcom,iommu-geometry = <0x40000000 0x10000000>;
			qcom,iommu-dma = "fastmap";
			ranges;
			status = "okay";
			phandle = <0x00000104>;
			qupv3_se4_2uart: qcom,qup_uart@4a90000 {
				compatible = "qcom,geni-debug-uart";
				reg = <0x04a90000 0x00004000>;
				reg-names = "se_phys";
				interrupts = <0x00000000 0x0000014b 0x00000004>;
				clock-names = "se";
				clocks = <&gcc 0x00000064>;
				interconnect-names = "qup-core", "qup-config", "qup-memory";
				interconnects = <&clk_virt 0x00000006 &clk_virt 0x00000202 &bimc 0x00000000 &config_noc 0x00000226 &system_noc 0x00000017 &bimc 0x00000200>;
				pinctrl-names = "default", "sleep";
				pinctrl-0 = <0x00000102>;
				pinctrl-1 = <0x00000103>;
				qcom,wrapper-core = <0x00000104>;
				status = "disabled";
				phandle = <0x00000233>;
			};
			qupv3_se3_4uart: qcom,qup_uart@4a8c000 {
				compatible = "qcom,msm-geni-serial-hs";
				reg = <0x04a8c000 0x00004000>;
				reg-names = "se_phys";
				clock-names = "se-clk";
				clocks = <&gcc 0x00000062>;
				interconnect-names = "qup-core", "qup-config", "qup-memory";
				interconnects = <&clk_virt 0x00000006 &clk_virt 0x00000202 &bimc 0x00000000 &config_noc 0x00000226 &system_noc 0x00000017 &bimc 0x00000200>;
				dmas = <&gpi_dma0 0x00000000 0x00000001 0x00000002 0x00000040 0x00000000 &gpi_dma0 0x00000001 0x00000001 0x00000002 0x00000040 0x00000000>;
				dma-names = "tx", "rx";
				pinctrl-names = "default", "active", "sleep", "shutdown";
				interrupts-extended = <&intc 0x00000000 0x0000014a 0x00000004 &tlmm 0x0000000b 0x00000004>;
				pinctrl-0 = <0x00000106 0x00000107 0x00000108 0x00000109>;
				pinctrl-1 = <0x0000010a 0x0000010b 0x0000010c 0x0000010d>;
				pinctrl-2 = <0x0000010a 0x0000010b 0x0000010c 0x00000109>;
				pinctrl-3 = <0x00000106 0x00000107 0x00000108 0x00000109>;
				qcom,wrapper-core = <0x00000104>;
				qcom,wakeup-byte = <0x000000fd>;
				status = "okay";
				phandle = <0x00000234>;
			};
			qupv3_se1_i2c: i2c@4a84000 {
				compatible = "qcom,i2c-geni";
				reg = <0x04a84000 0x00004000>;
				#address-cells = <0x00000001>;
				#size-cells = <0x00000000>;
				interrupts = <0x00000000 0x00000148 0x00000004>;
				clock-names = "se-clk";
				clocks = <&gcc 0x0000005e>;
				interconnect-names = "qup-core", "qup-config", "qup-memory";
				interconnects = <&clk_virt 0x00000006 &clk_virt 0x00000202 &bimc 0x00000000 &config_noc 0x00000226 &system_noc 0x00000017 &bimc 0x00000200>;
				dmas = <&gpi_dma0 0x00000000 0x00000001 0x00000003 0x00000040 0x00000000 &gpi_dma0 0x00000001 0x00000001 0x00000003 0x00000040 0x00000000>;
				dma-names = "tx", "rx";
				pinctrl-names = "default", "sleep";
				pinctrl-0 = <0x00000110>;
				pinctrl-1 = <0x00000111>;
				qcom,wrapper-core = <0x00000104>;
				status = "okay";
				qcom,leica-used-i2c;
				phandle = <0x000000c3>;
			};
			qupv3_se2_i2c: i2c@4a88000 {
				compatible = "qcom,i2c-geni";
				reg = <0x04a88000 0x00004000>;
				#address-cells = <0x00000001>;
				#size-cells = <0x00000000>;
				interrupts = <0x00000000 0x00000149 0x00000004>;
				clock-names = "se-clk";
				clocks = <&gcc 0x00000060>;
				interconnect-names = "qup-core", "qup-config", "qup-memory";
				interconnects = <&clk_virt 0x00000006 &clk_virt 0x00000202 &bimc 0x00000000 &config_noc 0x00000226 &system_noc 0x00000017 &bimc 0x00000200>;
				dmas = <&gpi_dma0 0x00000000 0x00000002 0x00000003 0x00000040 0x00000000 &gpi_dma0 0x00000001 0x00000002 0x00000003 0x00000040 0x00000000>;
				dma-names = "tx", "rx";
				pinctrl-names = "default", "sleep";
				pinctrl-0 = <0x00000118>;
				pinctrl-1 = <0x00000119>;
				qcom,wrapper-core = <0x00000104>;
				status = "disabled";
				phandle = <0x00000242>;
			};
			qupv3_se4_i2c: i2c@4a90000 {
				compatible = "qcom,i2c-geni";
				reg = <0x04a90000 0x00004000>;
				interrupts = <0x00000000 0x0000014b 0x00000004>;
				#address-cells = <0x00000001>;
				#size-cells = <0x00000000>;
				clock-names = "se-clk";
				clocks = <&gcc 0x00000064>;
				interconnect-names = "qup-core", "qup-config", "qup-memory";
				interconnects = <&clk_virt 0x00000006 &clk_virt 0x00000202 &bimc 0x00000000 &config_noc 0x00000226 &system_noc 0x00000017 &bimc 0x00000200>;
				dmas = <&gpi_dma0 0x00000000 0x00000004 0x00000003 0x00000040 0x00000000 &gpi_dma0 0x00000001 0x00000004 0x00000003 0x00000040 0x00000000>;
				dma-names = "tx", "rx";
				pinctrl-names = "default", "sleep";
				pinctrl-0 = <0x0000011a>;
				pinctrl-1 = <0x0000011b>;
				qcom,wrapper-core = <0x00000104>;
				status = "okay";
				phandle = <0x00000243>;
			};
			qupv3_se0_spi: spi@4a80000 {
				compatible = "qcom,spi-geni";
				#address-cells = <0x00000001>;
				#size-cells = <0x00000000>;
				interrupts = <0x00000000 0x00000147 0x00000004>;
				reg = <0x04a80000 0x00004000>;
				reg-names = "se_phys";
				clock-names = "se-clk";
				clocks = <&gcc 0x0000005c>;
				interconnect-names = "qup-core", "qup-config", "qup-memory";
				interconnects = <&clk_virt 0x00000006 &clk_virt 0x00000202 &bimc 0x00000000 &config_noc 0x00000226 &system_noc 0x00000017 &bimc 0x00000200>;
				pinctrl-names = "default", "sleep";
				pinctrl-0 = <0x0000011c>;
				pinctrl-1 = <0x0000011d>;
				spi-max-frequency = <0x02faf080>;
				qcom,wrapper-core = <0x00000104>;
				dmas = <&gpi_dma0 0x00000000 0x00000000 0x00000001 0x00000040 0x00000000 &gpi_dma0 0x00000001 0x00000000 0x00000001 0x00000040 0x00000000>;
				dma-names = "tx", "rx";
				status = "okay";
				phandle = <0x00000244>;
			};
		};
		lmh_dcvs0: qcom,limits-0-dcvs@f550800 {
			compatible = "qcom,msm-hw-limits";
			interrupts = <0x00000000 0x00000025 0x00000004>;
			qcom,affinity = <0x00000000>;
			reg = <0x0f550800 0x00001000 0x0f521000 0x00001000>;
			phandle = <0x00000006>;
		};
		lmh_dcvs1: qcom,limits-1-dcvs@f550800 {
			compatible = "qcom,msm-hw-limits";
			interrupts = <0x00000000 0x00000025 0x00000004>;
			qcom,affinity = <0x00000001>;
			reg = <0x0f550800 0x00001000 0x0f523000 0x00001000>;
			phandle = <0x0000000d>;
		};
		qcom,cpu-pause {
			compatible = "qcom,thermal-pause";
			cpu1_pause: cpu1-pause {
				qcom,cpus = <0x00000012>;
				#cooling-cells = <0x00000002>;
				phandle = <0x000000b6>;
			};
			cpu2_pause: cpu2-pause {
				qcom,cpus = <0x00000013>;
				#cooling-cells = <0x00000002>;
				phandle = <0x000000b7>;
			};
			cpu3_pause: cpu3-pause {
				qcom,cpus = <0x00000014>;
				#cooling-cells = <0x00000002>;
				phandle = <0x000000b8>;
			};
			cpu4_pause: cpu4-pause {
				qcom,cpus = <0x00000015>;
				#cooling-cells = <0x00000002>;
				phandle = <0x000000ab>;
			};
			cpu5_pause: cpu5-pause {
				qcom,cpus = <0x00000016>;
				#cooling-cells = <0x00000002>;
				phandle = <0x000000ad>;
			};
			cpu6_pause: cpu6-pause {
				qcom,cpus = <0x00000017>;
				#cooling-cells = <0x00000002>;
				phandle = <0x000000af>;
			};
			cpu7_pause: cpu7-pause {
				qcom,cpus = <0x00000018>;
				#cooling-cells = <0x00000002>;
				phandle = <0x000000b1>;
			};
		};
	};
};
